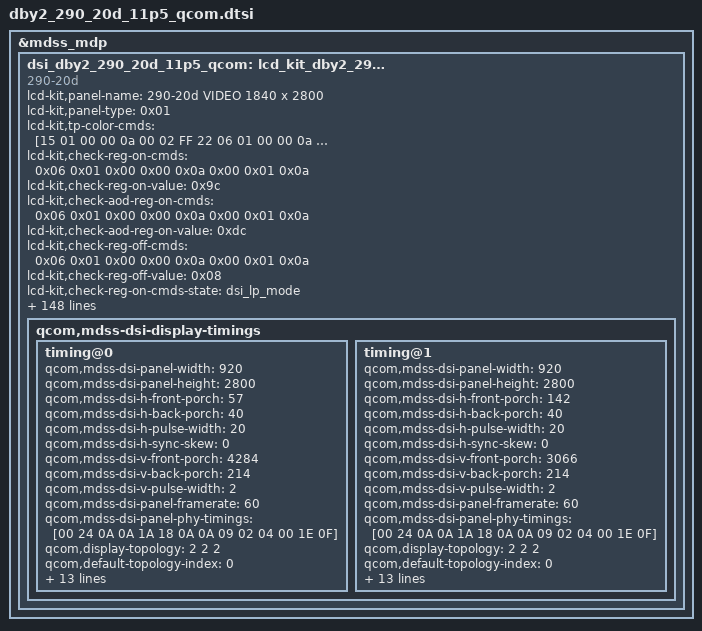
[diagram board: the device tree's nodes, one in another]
/* Copyright (c) 2013, The Linux Foundation. All rights reserved.
 *
 * This program is free software; you can redistribute it and/or modify
 * it under the terms of the GNU General Public License version 2 and
 * only version 2 as published by the Free Software Foundation.
 *
 * This program is distributed in the hope that it will be useful,
 * but WITHOUT ANY WARRANTY; without even the implied warranty of
 * MERCHANTABILITY or FITNESS FOR A PARTICULAR PURPOSE.  See the
 * GNU General Public License for more details.
 */

/*-------------------------------------------------------------------------
 * This file is autogenerated file using gcdb parser. Please do not edit it.
 * Update input XML file to add a new entry or update variable in this file
 * VERSION = 1.1
 *-----------------------------------------------------------------------*/
&mdss_mdp {
	dsi_dby2_290_20d_11p5_qcom: lcd_kit_dby2_290_20d_11p5_qcom {
		compatible = "290-20d";
		lcd-kit,panel-name = "290-20d VIDEO 1840 x 2800";
		lcd-kit,panel-type = <0x01>;
		lcd-kit,tp-color-cmds = [15 01 00 00 0a 00 02 FF 22
		06 01 00 00 0a 00 01 0A
		15 01 00 00 0a 00 02 FF 10];
		lcd-kit,check-reg-on-cmds = <0x06 0x01 0x00 0x00 0x0a 0x00 0x01 0x0a>;
		lcd-kit,check-reg-on-value = <0x9c>;
		lcd-kit,check-aod-reg-on-cmds = <0x06 0x01 0x00 0x00 0x0a 0x00 0x01 0x0a>;
		lcd-kit,check-aod-reg-on-value = <0xdc>;
		lcd-kit,check-reg-off-cmds = <0x06 0x01 0x00 0x00 0x0a 0x00 0x01 0x0a>;
		lcd-kit,check-reg-off-value = <0x08>;
		lcd-kit,check-reg-on-cmds-state = "dsi_lp_mode";
		lcd-kit,check-aod-reg-on-cmds-state = "dsi_lp_mode";
		lcd-kit,check-reg-off-cmds-state = "dsi_lp_mode";
		lcd-kit,project-id-cmds = [15 01 00 00 0a 00 02 FF 22
                06 01 00 00 0a 00 01 00
                06 01 00 00 0a 00 01 01
                06 01 00 00 0a 00 01 02
                06 01 00 00 0a 00 01 03
                06 01 00 00 0a 00 01 04
                06 01 00 00 0a 00 01 05
                06 01 00 00 0a 00 01 06
                06 01 00 00 0a 00 01 07
                06 01 00 00 0a 00 01 08
                06 01 00 00 0a 00 01 09
                15 01 00 00 0a 00 02 FF 10];
		lcd-kit,project-id-cmds-state = "dsi_lp_mode";
		lcd-kit,panel-version-cmds = [39 01 00 00 00 00 02 FF 22
		14 01 00 00 0a 00 01 01];
		lcd-kit,bl-after-frame = <0>;
		lcd-kit,cmd-async-support = <0>;
		lcd-kit,check-reg-on-support = <0>;
		lcd-kit,check-reg-on-support-dsm-report = <0>;
		lcd-kit,check-aod-reg-on-support = <0>;
		lcd-kit,check-aod-reg-on-support-dsm-report = <0>;
		lcd-kit,check-reg-off-support = <0>;
		lcd-kit,check-reg-off-support-dsm-report = <0>;
		lcd-kit,vtc-line-no-reset = <1>;
		qcom,mdss-dsi-panel-type = "dsi_video_mode";
		qcom,mdss-dsi-panel-name = "290-20d-11p5";
		qcom,mdss-pan-physical-width-dimension = <173>;
		qcom,mdss-pan-physical-height-dimension = <258>;
		qcom,dsi-ctrl-num = <0 1>;
		qcom,dsi-phy-num = <0 1>;
		qcom,panel-supply-entries = <&dsi_panel_pwr_supply>;
		qcom,mdss-dsi-virtual-channel-id = <0>;
		qcom,mdss-dsi-h-sync-pulse = <0>;
		qcom,mdss-dsi-bllp-eof-power-mode;
		qcom,mdss-dsi-bllp-power-mode;
		qcom,mdss-dsi-dma-schedule-line = <1>;
		qcom,mdss-dsi-bpp = <24>;
		qcom,mdss-dsi-color-order = "rgb_swap_rgb";
		qcom,mdss-dsi-underflow-color = <0xff>;
		qcom,mdss-dsi-border-color = <0>;
		qcom,mdss-dsi-traffic-mode = "burst_mode";
		qcom,mdss-dsi-lane-map = "lane_map_0123";
		qcom,mdss-dsi-lane-0-state;
		qcom,mdss-dsi-lane-1-state;
		qcom,mdss-dsi-lane-2-state;
		qcom,mdss-dsi-lane-3-state;
		qcom,mdss-dsi-mdp-trigger = "none";
		qcom,mdss-dsi-dma-trigger = "trigger_sw";
		qcom,mdss-dsi-te-pin-select = <0>;
		qcom,mdss-dsi-t-clk-post = <0>;
		qcom,mdss-dsi-t-clk-pre = <0>;
		qcom,dsi-select-clocks = "mux_byte_clk0", "mux_pixel_clk0";
		qcom,mdss-dsi-stream = <0>;
		qcom,cmd-sync-wait-broadcast;
		qcom,mdss-dsi-lp11-init;
		lcd-kit,check-thread-support = <0>;
		lcd-kit,check-time-period = <5000>;
		lcd-kit,check-fold-support = <0>;
		lcd-kit,fold-low-power-support = <0>;
		lcd-kit,fold-height = <0>;
		lcd-kit,unfold-height = <0>;
		lcd-kit,power-support = <0>;
		lcd-kit,three-stage-poweron = <0>;
		qcom,apaod-lp2-need-sendcmd;
		lcd-kit,fold-lp-time = <0>;
		lcd-kit,fold-nolp-time = <0>;
		qcom,sublinks-count = <2>;
		qcom,lanes-per-sublink = <2>;
		qcom,mdss-dsi-panel-hdr-color-primaries = <14500 15500 32000 17000 15500 30000 8000 3000>;
		qcom,mdss-dsi-panel-peak-brightness = <4200000>;
		qcom,mdss-dsi-panel-blackness-level = <3230>;
		qcom,dynamic-mode-switch-enabled;
		qcom,dynamic-mode-switch-type = "dynamic-resolution-switch-immediate";
		qcom,mdss-dsi-bl-pmic-control-type = "bl_ctrl_i2c_ic";
		qcom,mdss-dsi-bl-min-level = <1>;
		qcom,mdss-dsi-bl-max-level = <4095>;
		qcom,tp-suspend-before-lcd;
		qcom,esd-check-enabled;
		qcom,tp-esd-gpio-event;
		qcom,esd-gpio-detect-support;
		qcom,esd-only-gpio-detect;
		qcom,esd-gpio-detect-num0 = <119>;
		qcom,esd-gpio-normal-value0 = <0>;
		qcom,esd-gpio-detect-num1 = <115>;
		qcom,esd-gpio-normal-value1 = <0>;
		qcom,mdss-dsi-panel-status-command = [15 01 00 00 00 00 02 FF 10
			06 01 00 00 00 00 01 0A];
		qcom,mdss-dsi-panel-status-command-state = "dsi_lp_mode";
		qcom,mdss-dsi-panel-status-check-mode = "reg_read";
		qcom,mdss-dsi-panel-status-read-length = <0 1>;
		qcom,mdss-dsi-panel-status-value = <0x9C>;
		lcd-kit,power-on-stage = <2 1 10
				3 1 2
				4 1 11
				11 1 1
				5 2 10
				5 1 10
				5 2 10
				5 1 10
				6 1 0>;
		lcd-kit,lp-on-stage = <7 1 5
				8 1 0>;
		lcd-kit,hs-off-stage = <7 0 0
				8 0 20>;
		lcd-kit,power-off-stage = <5 0 5
				6 0 10
				11 0 2
				4 0 5
				3 0 10
				2 0 0>;
		lcd-kit,only-power-off-stage = <0 0 0>;
		lcd-kit,panel-version-support = <1>;
		lcd-kit,panel-version = "CG","AG";
		lcd-kit,panel-version-value = <0xD2
				0x4B>;
		lcd-kit,pt-support = <0>;
		lcd-kit,panel-on-always-reset = <1>;
		lcd-kit,lcd-iovcc = <2 30 1800000>;
		lcd-kit,lcd-vsp = <2 44 5900000>;
		lcd-kit,lcd-vsn = <2 45 5900000>;
		lcd-kit,lcd-reset = <2 24 0>;
		lcd-kit,tp-reset = <2 27 0>;
		lcd-kit,lcd-vci-name = "vdd";
		lcd-kit,lcd-iovcc-name = "vddio";
		lcd-kit,project-id-support = <1>;
		lcd-kit,default-project-id = "W359B12700";
		lcd-kit,Does-lcd-poweron-tp = <1>;
		lcd-kit,sn-code-support = <0>;
		lcd-kit,oem-info-support = <0>;
		lcd-kit,oem-barcode-2d-support = <0>;
		lcd-kit,oem-barcode-2d-num-offset = <0>;
		lcd-kit,barcode-2d-cmds = <0x29 0x01 0x00 0x00 0x00 0x00 0x02 0xFF 0x22
                0x06 0x01 0x00 0x00 0x00 0x00 0x01 0x0B
                0x06 0x01 0x00 0x00 0x00 0x00 0x01 0x0C
                0x06 0x01 0x00 0x00 0x00 0x00 0x01 0x0D
                0x06 0x01 0x00 0x00 0x00 0x00 0x01 0x0E
                0x06 0x01 0x00 0x00 0x00 0x00 0x01 0x0F
                0x06 0x01 0x00 0x00 0x00 0x00 0x01 0x10
                0x06 0x01 0x00 0x00 0x00 0x00 0x01 0x11
                0x06 0x01 0x00 0x00 0x00 0x00 0x01 0x12
                0x06 0x01 0x00 0x00 0x00 0x00 0x01 0x13
                0x06 0x01 0x00 0x00 0x00 0x00 0x01 0x14
                0x06 0x01 0x00 0x00 0x00 0x00 0x01 0x15
                0x06 0x01 0x00 0x00 0x00 0x00 0x01 0x16
                0x06 0x01 0x00 0x00 0x00 0x00 0x01 0x17
                0x06 0x01 0x00 0x00 0x00 0x00 0x01 0x18
                0x06 0x01 0x00 0x00 0x00 0x00 0x01 0x19
                0x06 0x01 0x00 0x00 0x00 0x00 0x01 0x1A
                0x06 0x01 0x00 0x00 0x00 0x00 0x01 0x1B
                0x06 0x01 0x00 0x00 0x00 0x00 0x01 0x1C
                0x06 0x01 0x00 0x00 0x00 0x00 0x01 0x1D
                0x06 0x01 0x00 0x00 0x00 0x00 0x01 0x1E
                0x06 0x01 0x00 0x00 0x00 0x00 0x01 0x1F
                0x29 0x01 0x00 0x00 0x00 0x00 0x02 0xFF 0x10>;
		lcd-kit,barcode-2d-cmds-state = "dsi_lp_mode";
		lcd-kit,panel-getblmaxnit-type = <0>;
		lcd-kit,panel-blmaxnit-min-value = <400>;
		lcd-kit,inversion-support = <0>;
		lcd-kit,panel-gpio-offset = <308>;
		lcd-kit,finger-unlock-state-support = <0>;
		lcd-kit,esd-reg-te-check = <0>;
		lcd-kit,panel-bl-max-nit = <450>;
		lcd-kit,panel-bl-min = <30>;
		lcd-kit,panel-bl-max = <3932>;
		lcd-kit,panel-bl-def = <128>;
		lcd-kit,check-reg-support = <0>;
		lcd-kit,thp-proximity-support = <0>;
		lcd-kit,proximity-reset-delay-min = <65>;
		lcd-kit,lcd-power-down-vsp = <2 44 5000000>;
		lcd-kit,lcd-power-down-vsn = <2 45 5000000>;
		lcd-kit,backlight-order = <0>;
		lcd-kit,backlight-need-sync = <0>;
		lcd-kit,fps-support = <1>;
		lcd-kit,default-fps = <60>;
		lcd-kit,panel-support-fps-list = <30 60 120 144>;
		lcd-kit,fps-30-cmd = "vndservice call display.qservice 25 i32 5 i32 0";
		lcd-kit,fps-60-cmd = "vndservice call display.qservice 25 i32 3 i32 0";
		lcd-kit,fps-90-cmd = "vndservice call display.qservice 25 i32 3 i32 0";
		lcd-kit,fps-120-cmd = "vndservice call display.qservice 25 i32 1 i32 0";
		qcom,mdss-dsi-display-timings {
			timing@0 {
				qcom,mdss-dsi-panel-width = <920>;
				qcom,mdss-dsi-panel-height = <2800>;
				qcom,mdss-dsi-h-front-porch = <57>;
				qcom,mdss-dsi-h-back-porch = <40>;
				qcom,mdss-dsi-h-pulse-width = <20>;
				qcom,mdss-dsi-h-sync-skew = <0>;
				qcom,mdss-dsi-v-front-porch = <4284>;
				qcom,mdss-dsi-v-back-porch = <214>;
				qcom,mdss-dsi-v-pulse-width = <2>;
				qcom,mdss-dsi-panel-framerate = <60>;
				qcom,mdss-dsi-panel-phy-timings= [00 24 0A 0A 1A 18 0A
                        0A 09 02 04 00 1E 0F];
				qcom,display-topology  = <2 2 2>;
				qcom,default-topology-index  = <0>;
				qcom,mdss-dsi-on-command = [39 01 00 00 01 00 02 FF 10
				39 01 00 00 00 00 02 FB 01
				39 01 00 00 00 00 07 3B 03 D8 1A 0A 0A 00
				39 01 00 00 00 00 02 90 03
				39 01 00 00 00 00 11 91 89 28 00 14 C2 00 00 00 01 C2 00 06 05 0E 05 DD
				39 01 00 00 00 00 03 92 10 D0
				39 01 00 00 00 00 02 9D 01
				39 01 00 00 01 00 02 FF 25
				39 01 00 00 00 00 02 FB 01
				39 01 00 00 00 00 02 05 00
				39 01 00 00 00 00 02 0F 20
				39 01 00 00 01 00 02 FF 24
				39 01 00 00 00 00 02 FB 01
				39 01 00 00 00 00 02 95 09
				39 01 00 00 01 00 02 FF 26
				39 01 00 00 00 00 02 FB 01
				39 01 00 00 00 00 02 04 96
				39 01 00 00 01 00 02 FF 27
				39 01 00 00 00 00 02 FB 01
				39 01 00 00 00 00 02 D0 11
				39 01 00 00 00 00 02 DE 41
				39 01 00 00 00 00 02 DF 02
                                39 01 00 00 01 00 02 06 00
                                39 01 00 00 01 00 02 FF 2A
                                39 01 00 00 00 00 02 FB 01
                                39 01 00 00 00 00 02 30 03
                                39 01 00 00 00 00 02 33 FE
                                39 01 00 00 00 00 02 35 0C
				39 01 00 00 01 00 02 FF 20
				39 01 00 00 00 00 02 FB 01
				39 01 00 00 00 00 02 F2 00
				39 01 00 00 00 00 02 F5 00
				39 01 00 00 00 00 02 F9 00
				39 01 00 00 00 00 02 F3 00
				39 01 00 00 00 00 02 F6 00
				39 01 00 00 00 00 02 31 06
				39 01 00 00 00 00 02 32 76
				39 01 00 00 00 00 02 FF 27
				39 01 00 00 00 00 02 FB 01
				39 01 00 00 00 00 02 13 00
				39 01 00 00 01 00 02 FF 10
				05 01 00 00 64 00 01 11
				05 01 00 00 14 00 01 29
			];
				qcom,mdss-dsi-on-command-state = "dsi_lp_mode";
				qcom,mdss-dsi-off-command = [05 01 00 00 32 00 01 28
			05 01 00 00 78 00 01 10];
				qcom,mdss-dsi-off-command-state = "dsi_lp_mode";
				qcom,compression-mode = "dsc";
				qcom,mdss-dsc-slice-height = <20>;
				qcom,mdss-dsc-slice-width = <460>;
				qcom,mdss-dsc-slice-per-pkt = <1>;
				qcom,mdss-dsc-bit-per-component = <8>;
				qcom,mdss-dsc-bit-per-pixel = <8>;
				qcom,mdss-dsc-block-prediction-enable;
			};
			timing@1 {
				qcom,mdss-dsi-panel-width = <920>;
				qcom,mdss-dsi-panel-height = <2800>;
				qcom,mdss-dsi-h-front-porch = <142>;
				qcom,mdss-dsi-h-back-porch = <40>;
				qcom,mdss-dsi-h-pulse-width = <20>;
				qcom,mdss-dsi-h-sync-skew = <0>;
				qcom,mdss-dsi-v-front-porch = <3066>;
				qcom,mdss-dsi-v-back-porch = <214>;
				qcom,mdss-dsi-v-pulse-width = <2>;
				qcom,mdss-dsi-panel-framerate = <60>;
				qcom,mdss-dsi-panel-phy-timings= [00 24 0A 0A 1A 18 0A
                        0A 09 02 04 00 1E 0F];
				qcom,display-topology  = <2 2 2>;
				qcom,default-topology-index  = <0>;
				qcom,mdss-dsi-on-command = [39 01 00 00 01 00 02 FF 10
				39 01 00 00 00 00 02 FB 01
				39 01 00 00 00 00 07 3B 03 D8 1A 0A 0A 00
				39 01 00 00 00 00 02 90 03
				39 01 00 00 00 00 11 91 89 28 00 14 C2 00 00 00 01 C2 00 06 05 0E 05 DD
				39 01 00 00 00 00 03 92 10 D0
				39 01 00 00 00 00 02 9D 01
				39 01 00 00 01 00 02 FF 25
				39 01 00 00 00 00 02 FB 01
				39 01 00 00 00 00 02 05 00
				39 01 00 00 00 00 02 0F 20
				39 01 00 00 01 00 02 FF 24
				39 01 00 00 00 00 02 FB 01
				39 01 00 00 00 00 02 95 09
				39 01 00 00 01 00 02 FF 26
				39 01 00 00 00 00 02 FB 01
				39 01 00 00 00 00 02 04 96
				39 01 00 00 01 00 02 FF 27
				39 01 00 00 00 00 02 FB 01
				39 01 00 00 00 00 02 D0 11
				39 01 00 00 00 00 02 DE 41
				39 01 00 00 00 00 02 DF 02
                                39 01 00 00 01 00 02 06 00
                                39 01 00 00 01 00 02 FF 2A
                                39 01 00 00 00 00 02 FB 01
                                39 01 00 00 00 00 02 30 03
                                39 01 00 00 00 00 02 33 FE
                                39 01 00 00 00 00 02 35 0C
				39 01 00 00 01 00 02 FF 20
				39 01 00 00 00 00 02 FB 01
				39 01 00 00 00 00 02 F2 00
				39 01 00 00 00 00 02 F5 00
				39 01 00 00 00 00 02 F9 00
				39 01 00 00 00 00 02 F3 00
				39 01 00 00 00 00 02 F6 00
				39 01 00 00 00 00 02 31 06
				39 01 00 00 00 00 02 32 76
				39 01 00 00 00 00 02 FF 27
				39 01 00 00 00 00 02 FB 01
				39 01 00 00 00 00 02 13 00
				39 01 00 00 01 00 02 FF 10
				05 01 00 00 64 00 01 11
				05 01 00 00 14 00 01 29
                       ];
				qcom,mdss-dsi-on-command-state = "dsi_lp_mode";
				qcom,mdss-dsi-off-command = [05 01 00 00 32 00 01 28
                        05 01 00 00 78 00 01 10];
				qcom,mdss-dsi-off-command-state = "dsi_lp_mode";
				qcom,compression-mode = "dsc";
				qcom,mdss-dsc-slice-height = <20>;
				qcom,mdss-dsc-slice-width = <460>;
				qcom,mdss-dsc-slice-per-pkt = <1>;
				qcom,mdss-dsc-bit-per-component = <8>;
				qcom,mdss-dsc-bit-per-pixel = <8>;
				qcom,mdss-dsc-block-prediction-enable;
			};
		};
    };
};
